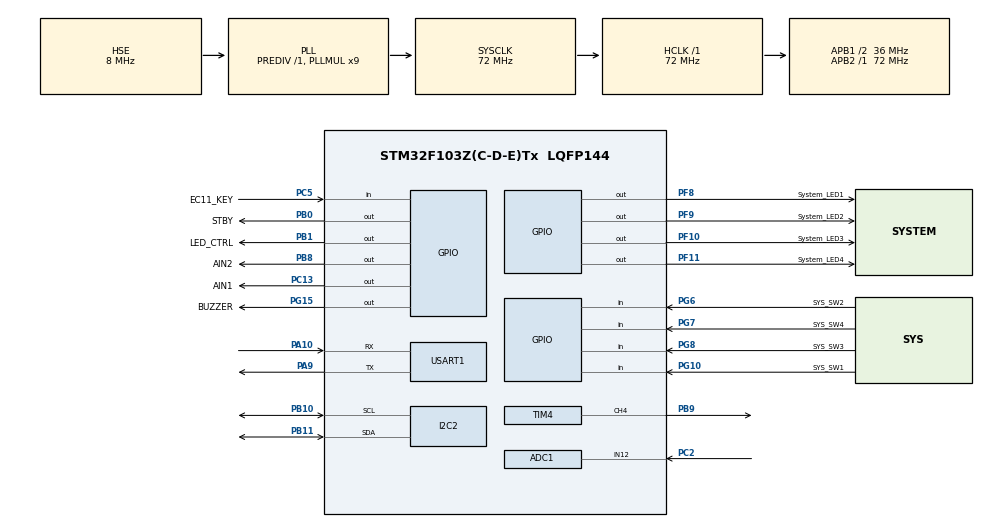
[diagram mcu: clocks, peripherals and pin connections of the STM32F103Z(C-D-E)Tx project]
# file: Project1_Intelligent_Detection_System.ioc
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ADC1.Channel-0\#ChannelRegularConversion=ADC_CHANNEL_12
ADC1.ContinuousConvMode=ENABLE
ADC1.NbrOfConversionFlag=1
ADC1.Rank-0\#ChannelRegularConversion=1
ADC1.SamplingTime-0\#ChannelRegularConversion=ADC_SAMPLETIME_1CYCLE_5
ADC1.master=1
Dma.I2C2_RX.0.Direction=DMA_PERIPH_TO_MEMORY
Dma.I2C2_RX.0.Instance=DMA1_Channel5
Dma.I2C2_RX.0.MemDataAlignment=DMA_MDATAALIGN_BYTE
Dma.I2C2_RX.0.MemInc=DMA_MINC_ENABLE
Dma.I2C2_RX.0.Mode=DMA_NORMAL
Dma.I2C2_RX.0.PeriphDataAlignment=DMA_PDATAALIGN_BYTE
Dma.I2C2_RX.0.PeriphInc=DMA_PINC_DISABLE
Dma.I2C2_RX.0.Priority=DMA_PRIORITY_LOW
Dma.I2C2_TX.1.Direction=DMA_MEMORY_TO_PERIPH
Dma.I2C2_TX.1.Instance=DMA1_Channel4
Dma.I2C2_TX.1.MemDataAlignment=DMA_MDATAALIGN_BYTE
Dma.I2C2_TX.1.MemInc=DMA_MINC_ENABLE
Dma.I2C2_TX.1.Mode=DMA_NORMAL
Dma.I2C2_TX.1.PeriphDataAlignment=DMA_PDATAALIGN_BYTE
Dma.I2C2_TX.1.PeriphInc=DMA_PINC_DISABLE
Dma.I2C2_TX.1.Priority=DMA_PRIORITY_LOW
Dma.Request0=I2C2_RX
Dma.Request1=I2C2_TX
Mcu.Family=STM32F1
Mcu.Name=STM32F103Z(C-D-E)Tx
Mcu.Package=LQFP144
NVIC.ADC1_2_IRQn=true\:0\:0\:false\:false\:true\:true\:true\:true
NVIC.DMA1_Channel4_IRQn=true\:0\:0\:false\:false\:true\:false\:true\:true
NVIC.DMA1_Channel5_IRQn=true\:0\:0\:false\:false\:true\:false\:true\:true
NVIC.I2C2_EV_IRQn=true\:0\:0\:false\:false\:true\:true\:true\:true
NVIC.PriorityGroup=NVIC_PRIORITYGROUP_4
NVIC.TIM2_IRQn=true\:0\:0\:false\:false\:true\:true\:true\:true
OSC_IN.Mode=HSE-External-Oscillator
OSC_IN.Signal=RCC_OSC_IN
OSC_OUT.Mode=HSE-External-Oscillator
OSC_OUT.Signal=RCC_OSC_OUT
PA10.Mode=Asynchronous
PA10.Signal=USART1_RX
PA13.Mode=Serial_Wire
PA13.Signal=SYS_JTMS-SWDIO
PA14.Mode=Serial_Wire
PA14.Signal=SYS_JTCK-SWCLK
PA9.Mode=Asynchronous
PA9.Signal=USART1_TX
PB0.GPIO_Label=STBY
PB0.Signal=GPIO_Output
PB1.GPIO_Label=LED_CTRL
PB1.Signal=GPIO_Output
PB10.Mode=I2C
PB10.Signal=I2C2_SCL
PB11.Mode=I2C
PB11.Signal=I2C2_SDA
PB8.GPIO_Label=AIN2
PB8.Signal=GPIO_Output
PB9.Signal=S_TIM4_CH4
PC13-TAMPER-RTC.GPIO_Label=AIN1
PC13-TAMPER-RTC.Signal=GPIO_Output
PC2.Signal=ADCx_IN12
PC5.GPIO_Label=EC11_KEY
PC5.Signal=GPIO_Input
PF10.GPIO_Label=System_LED3
PF10.PinState=GPIO_PIN_SET
PF10.Signal=GPIO_Output
PF11.GPIO_Label=System_LED4
PF11.PinState=GPIO_PIN_SET
PF11.Signal=GPIO_Output
PF8.GPIO_Label=System_LED1
PF8.PinState=GPIO_PIN_SET
PF8.Signal=GPIO_Output
PF9.GPIO_Label=System_LED2
PF9.PinState=GPIO_PIN_SET
PF9.Signal=GPIO_Output
PG10.GPIO_Label=SYS_SW1
PG10.Signal=GPIO_Input
PG15.GPIO_Label=BUZZER
PG15.Signal=GPIO_Output
PG6.GPIO_Label=SYS_SW2
PG6.Signal=GPIO_Input
PG7.GPIO_Label=SYS_SW4
PG7.Signal=GPIO_Input
PG8.GPIO_Label=SYS_SW3
PG8.Signal=GPIO_Input
ProjectManager.HeapSize=0x200
ProjectManager.StackSize=0x400
ProjectManager.TargetToolchain=MDK-ARM V5.32
RCC.ADCPresc=RCC_ADCPCLK2_DIV6
RCC.AHBFreq_Value=72000000
RCC.APB1CLKDivider=RCC_HCLK_DIV2
RCC.APB1Freq_Value=36000000
RCC.APB1TimFreq_Value=72000000
RCC.APB2Freq_Value=72000000
RCC.APB2TimFreq_Value=72000000
RCC.HCLKFreq_Value=72000000
RCC.PLLMUL=RCC_PLL_MUL9
RCC.PLLSourceVirtual=RCC_PLLSOURCE_HSE
RCC.SYSCLKFreq_VALUE=72000000
RCC.SYSCLKSource=RCC_SYSCLKSOURCE_PLLCLK
RCC.USBFreq_Value=72000000
SH.ADCx_IN12.0=ADC1_IN12,IN12
SH.S_TIM4_CH4.0=TIM4_CH4,PWM Generation4 CH4
TIM2.AutoReloadPreload=TIM_AUTORELOAD_PRELOAD_ENABLE
TIM2.Period=1999
TIM2.Prescaler=71
TIM4.AutoReloadPreload=TIM_AUTORELOAD_PRELOAD_ENABLE
TIM4.Channel-PWM\ Generation4\ CH4=TIM_CHANNEL_4
TIM4.Period=999
TIM4.Prescaler=71
USART1.VirtualMode=VM_ASYNC
VP_TIM2_VS_ClockSourceINT.Mode=Internal
VP_TIM4_VS_ClockSourceINT.Mode=Internal
board=custom

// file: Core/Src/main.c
/* USER CODE BEGIN Header */
/**
  ******************************************************************************
  * @file           : main.c
  * @brief          : Main program body
  ******************************************************************************
  * @attention
  *
  * Copyright (c) 2026 STMicroelectronics.
  * All rights reserved.
  *
  * This software is licensed under terms that can be found in the LICENSE file
  * in the root directory of this software component.
  * If no LICENSE file comes with this software, it is provided AS-IS.
  *
  ******************************************************************************
  */
/* USER CODE END Header */
#include "main.h"
#include "adc.h"
#include "dma.h"
#include "i2c.h"
#include "tim.h"
#include "usart.h"
#include "gpio.h"

/* USER CODE BEGIN Includes */
#include "app.h"
/* USER CODE END Includes */

void SystemClock_Config(void);

int main(void)
{

  /* MCU Configuration--------------------------------------------------------*/

  /* Reset of all peripherals, Initializes the Flash interface and the Systick. */
  HAL_Init();

  /* Configure the system clock */
  SystemClock_Config();

  /* Initialize all configured peripherals */
  MX_GPIO_Init();
  MX_DMA_Init();
  MX_USART1_UART_Init();
  MX_I2C2_Init();
  MX_ADC1_Init();
  MX_TIM2_Init();
  MX_TIM4_Init();
  /* USER CODE BEGIN 2 */
  app_init();
  app_start();
  /* USER CODE END 2 */

  /* Infinite loop */
  while (1)
  {

  }
}

void SystemClock_Config(void)
{
  RCC_OscInitTypeDef RCC_OscInitStruct = {0};
  RCC_ClkInitTypeDef RCC_ClkInitStruct = {0};
  RCC_PeriphCLKInitTypeDef PeriphClkInit = {0};

  /** Initializes the RCC Oscillators according to the specified parameters
  * in the RCC_OscInitTypeDef structure.
  */
  RCC_OscInitStruct.OscillatorType = RCC_OSCILLATORTYPE_HSE;
  RCC_OscInitStruct.HSEState = RCC_HSE_ON;
  RCC_OscInitStruct.HSEPredivValue = RCC_HSE_PREDIV_DIV1;
  RCC_OscInitStruct.HSIState = RCC_HSI_ON;
  RCC_OscInitStruct.PLL.PLLState = RCC_PLL_ON;
  RCC_OscInitStruct.PLL.PLLSource = RCC_PLLSOURCE_HSE;
  RCC_OscInitStruct.PLL.PLLMUL = RCC_PLL_MUL9;
  if (HAL_RCC_OscConfig(&RCC_OscInitStruct) != HAL_OK)
  {
    Error_Handler();
  }

  /** Initializes the CPU, AHB and APB buses clocks
  */
  RCC_ClkInitStruct.ClockType = RCC_CLOCKTYPE_HCLK|RCC_CLOCKTYPE_SYSCLK
                              |RCC_CLOCKTYPE_PCLK1|RCC_CLOCKTYPE_PCLK2;
  RCC_ClkInitStruct.SYSCLKSource = RCC_SYSCLKSOURCE_PLLCLK;
  RCC_ClkInitStruct.AHBCLKDivider = RCC_SYSCLK_DIV1;
  RCC_ClkInitStruct.APB1CLKDivider = RCC_HCLK_DIV2;
  RCC_ClkInitStruct.APB2CLKDivider = RCC_HCLK_DIV1;

  if (HAL_RCC_ClockConfig(&RCC_ClkInitStruct, FLASH_LATENCY_2) != HAL_OK)
  {
    Error_Handler();
  }
  PeriphClkInit.PeriphClockSelection = RCC_PERIPHCLK_ADC;
  PeriphClkInit.AdcClockSelection = RCC_ADCPCLK2_DIV6;
  if (HAL_RCCEx_PeriphCLKConfig(&PeriphClkInit) != HAL_OK)
  {
    Error_Handler();
  }
}

void Error_Handler(void)
{
  __disable_irq();
  while (1)
  {
  }
}
